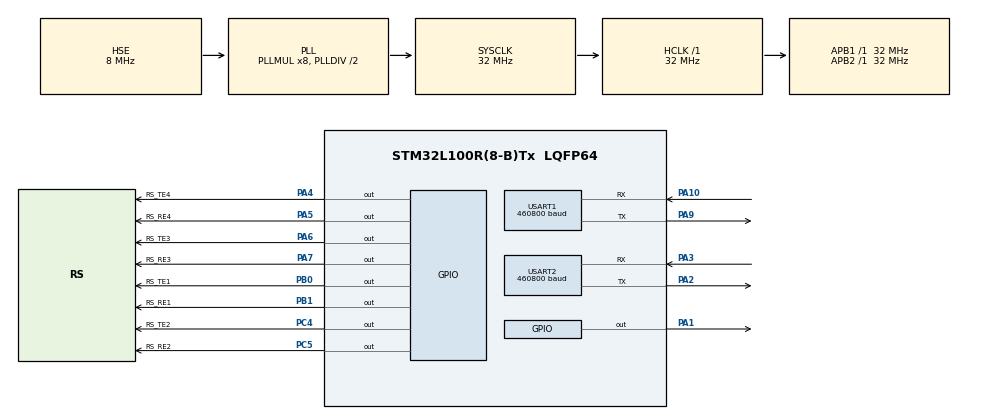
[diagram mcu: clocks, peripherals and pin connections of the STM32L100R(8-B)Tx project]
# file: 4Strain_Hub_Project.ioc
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Mcu.Family=STM32L1
Mcu.Name=STM32L100R(8-B)Tx
Mcu.Package=LQFP64
NVIC.PriorityGroup=NVIC_PRIORITYGROUP_4
NVIC.RCC_IRQn=true\:0\:0\:false\:false\:true\:true
NVIC.TIM10_IRQn=true\:2\:0\:true\:false\:true\:true
NVIC.USART1_IRQn=true\:5\:0\:true\:false\:true\:true
NVIC.USART2_IRQn=true\:1\:0\:true\:false\:true\:true
PA1.GPIO_Speed=GPIO_SPEED_FREQ_VERY_HIGH
PA1.Signal=GPIO_Output
PA10.Mode=Asynchronous
PA10.Signal=USART1_RX
PA13.Mode=Serial_Wire
PA13.Signal=SYS_JTMS-SWDIO
PA14.Mode=Serial_Wire
PA14.Signal=SYS_JTCK-SWCLK
PA2.Mode=Asynchronous
PA2.Signal=USART2_TX
PA3.Mode=Asynchronous
PA3.Signal=USART2_RX
PA4.GPIO_Label=RS_TE4
PA4.GPIO_PuPd=GPIO_NOPULL
PA4.GPIO_Speed=GPIO_SPEED_FREQ_VERY_HIGH
PA4.Signal=GPIO_Output
PA5.GPIO_Label=RS_RE4
PA5.GPIO_PuPd=GPIO_NOPULL
PA5.GPIO_Speed=GPIO_SPEED_FREQ_VERY_HIGH
PA5.Signal=GPIO_Output
PA6.GPIO_Label=RS_TE3
PA6.GPIO_PuPd=GPIO_NOPULL
PA6.GPIO_Speed=GPIO_SPEED_FREQ_VERY_HIGH
PA6.Signal=GPIO_Output
PA7.GPIO_Label=RS_RE3
PA7.GPIO_PuPd=GPIO_NOPULL
PA7.GPIO_Speed=GPIO_SPEED_FREQ_VERY_HIGH
PA7.Signal=GPIO_Output
PA9.Mode=Asynchronous
PA9.Signal=USART1_TX
PB0.GPIO_Label=RS_TE1
PB0.GPIO_PuPd=GPIO_NOPULL
PB0.GPIO_Speed=GPIO_SPEED_FREQ_VERY_HIGH
PB0.Signal=GPIO_Output
PB1.GPIO_Label=RS_RE1
PB1.GPIO_PuPd=GPIO_NOPULL
PB1.GPIO_Speed=GPIO_SPEED_FREQ_VERY_HIGH
PB1.Signal=GPIO_Output
PC4.GPIO_Label=RS_TE2
PC4.GPIO_PuPd=GPIO_NOPULL
PC4.GPIO_Speed=GPIO_SPEED_FREQ_VERY_HIGH
PC4.Signal=GPIO_Output
PC5.GPIO_Label=RS_RE2
PC5.GPIO_PuPd=GPIO_NOPULL
PC5.GPIO_Speed=GPIO_SPEED_FREQ_VERY_HIGH
PC5.Signal=GPIO_Output
PH0-OSC_IN.Mode=HSE-External-Oscillator
PH0-OSC_IN.Signal=RCC_OSC_IN
PH1-OSC_OUT.Mode=HSE-External-Oscillator
PH1-OSC_OUT.Signal=RCC_OSC_OUT
ProjectManager.HeapSize=0x200
ProjectManager.StackSize=0x400
ProjectManager.TargetToolchain=MDK-ARM V5
RCC.48MHZClocksFreq_Value=32000000
RCC.AHBFreq_Value=32000000
RCC.APB1Freq_Value=32000000
RCC.APB1TimFreq_Value=32000000
RCC.APB2Freq_Value=32000000
RCC.APB2TimFreq_Value=32000000
RCC.HCLKFreq_Value=32000000
RCC.HSE_VALUE=8000000
RCC.HSI_VALUE=16000000
RCC.LSE_VALUE=32768
RCC.MSI_VALUE=2097000
RCC.PLLMUL=RCC_PLL_MUL8
RCC.PLLSourceVirtual=RCC_PLLSOURCE_HSE
RCC.SYSCLKFreq_VALUE=32000000
RCC.SYSCLKSource=RCC_SYSCLKSOURCE_PLLCLK
RCC.VCOOutputFreq_Value=64000000
TIM10.Period=10000
TIM10.Prescaler=31
USART1.BaudRate=460800
USART1.VirtualMode=VM_ASYNC
USART2.BaudRate=460800
USART2.VirtualMode=VM_ASYNC
VP_TIM10_VS_ClockSourceINT.Mode=Internal
board=custom

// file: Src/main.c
/**
  ******************************************************************************
  * @file           : main.c
  * @brief          : Main program body
  ******************************************************************************
  ** This notice applies to any and all portions of this file
  * that are not between comment pairs USER CODE BEGIN and
  * USER CODE END. Other portions of this file, whether
  * inserted by the user or by software development tools
  * are owned by their respective copyright owners.
  *
  * COPYRIGHT(c) 2018 STMicroelectronics
  *
  * Redistribution and use in source and binary forms, with or without modification,
  * are permitted provided that the following conditions are met:
  *   1. Redistributions of source code must retain the above copyright notice,
  *      this list of conditions and the following disclaimer.
  *   2. Redistributions in binary form must reproduce the above copyright notice,
  *      this list of conditions and the following disclaimer in the documentation
  *      and/or other materials provided with the distribution.
  *   3. Neither the name of STMicroelectronics nor the names of its contributors
  *      may be used to endorse or promote products derived from this software
  *      without specific prior written permission.
  *
  * THIS SOFTWARE IS PROVIDED BY THE COPYRIGHT HOLDERS AND CONTRIBUTORS "AS IS"
  * AND ANY EXPRESS OR IMPLIED WARRANTIES, INCLUDING, BUT NOT LIMITED TO, THE
  * IMPLIED WARRANTIES OF MERCHANTABILITY AND FITNESS FOR A PARTICULAR PURPOSE ARE
  * DISCLAIMED. IN NO EVENT SHALL THE COPYRIGHT HOLDER OR CONTRIBUTORS BE LIABLE
  * FOR ANY DIRECT, INDIRECT, INCIDENTAL, SPECIAL, EXEMPLARY, OR CONSEQUENTIAL
  * DAMAGES (INCLUDING, BUT NOT LIMITED TO, PROCUREMENT OF SUBSTITUTE GOODS OR
  * SERVICES; LOSS OF USE, DATA, OR PROFITS; OR BUSINESS INTERRUPTION) HOWEVER
  * CAUSED AND ON ANY THEORY OF LIABILITY, WHETHER IN CONTRACT, STRICT LIABILITY,
  * OR TORT (INCLUDING NEGLIGENCE OR OTHERWISE) ARISING IN ANY WAY OUT OF THE USE
  * OF THIS SOFTWARE, EVEN IF ADVISED OF THE POSSIBILITY OF SUCH DAMAGE.
  *
  ******************************************************************************
  */
#include "main.h"
#include "stm32l1xx_hal.h"

TIM_HandleTypeDef htim10;

UART_HandleTypeDef huart1;
UART_HandleTypeDef huart2;

/* USER CODE BEGIN PV */
/* Private variables ---------------------------------------------------------*/
uint8_t x, data0;
/* USER CODE END PV */

void SystemClock_Config(void);
static void MX_GPIO_Init(void);
static void MX_TIM10_Init(void);
static void MX_USART2_UART_Init(void);
static void MX_USART1_UART_Init(void);

/* USER CODE BEGIN PFP */
/* Private function prototypes -----------------------------------------------*/

/* USER CODE END PFP */

int main(void)
{

  /* MCU Configuration----------------------------------------------------------*/

  /* Reset of all peripherals, Initializes the Flash interface and the Systick. */
  HAL_Init();

  /* Configure the system clock */
  SystemClock_Config();

  /* Initialize all configured peripherals */
  MX_GPIO_Init();
  MX_TIM10_Init();
  MX_USART2_UART_Init();
  MX_USART1_UART_Init();
  /* USER CODE BEGIN 2 */

	x = 1;

	USART2->CR1 |= USART_CR1_RXNEIE;

	HAL_TIM_Base_Start(&htim10);
	HAL_TIM_Base_Start_IT(&htim10);

  /* USER CODE END 2 */

  /* Infinite loop */
  /* USER CODE BEGIN WHILE */
  while (1)
  {
	HAL_UART_Receive_IT(&huart2, &data0, 1);
  /* USER CODE END WHILE */

  }

}

void SystemClock_Config(void)
{

  RCC_OscInitTypeDef RCC_OscInitStruct;
  RCC_ClkInitTypeDef RCC_ClkInitStruct;

    /**Configure the main internal regulator output voltage
    */
  __HAL_PWR_VOLTAGESCALING_CONFIG(PWR_REGULATOR_VOLTAGE_SCALE1);

    /**Initializes the CPU, AHB and APB busses clocks
    */
  RCC_OscInitStruct.OscillatorType = RCC_OSCILLATORTYPE_HSE;
  RCC_OscInitStruct.HSEState = RCC_HSE_ON;
  RCC_OscInitStruct.PLL.PLLState = RCC_PLL_ON;
  RCC_OscInitStruct.PLL.PLLSource = RCC_PLLSOURCE_HSE;
  RCC_OscInitStruct.PLL.PLLMUL = RCC_PLL_MUL8;
  RCC_OscInitStruct.PLL.PLLDIV = RCC_PLL_DIV2;
  if (HAL_RCC_OscConfig(&RCC_OscInitStruct) != HAL_OK)
  {
    _Error_Handler(__FILE__, __LINE__);
  }

    /**Initializes the CPU, AHB and APB busses clocks
    */
  RCC_ClkInitStruct.ClockType = RCC_CLOCKTYPE_HCLK|RCC_CLOCKTYPE_SYSCLK
                              |RCC_CLOCKTYPE_PCLK1|RCC_CLOCKTYPE_PCLK2;
  RCC_ClkInitStruct.SYSCLKSource = RCC_SYSCLKSOURCE_PLLCLK;
  RCC_ClkInitStruct.AHBCLKDivider = RCC_SYSCLK_DIV1;
  RCC_ClkInitStruct.APB1CLKDivider = RCC_HCLK_DIV1;
  RCC_ClkInitStruct.APB2CLKDivider = RCC_HCLK_DIV1;

  if (HAL_RCC_ClockConfig(&RCC_ClkInitStruct, FLASH_LATENCY_1) != HAL_OK)
  {
    _Error_Handler(__FILE__, __LINE__);
  }

    /**Configure the Systick interrupt time
    */
  HAL_SYSTICK_Config(HAL_RCC_GetHCLKFreq()/1000);

    /**Configure the Systick
    */
  HAL_SYSTICK_CLKSourceConfig(SYSTICK_CLKSOURCE_HCLK);

  /* SysTick_IRQn interrupt configuration */
  HAL_NVIC_SetPriority(SysTick_IRQn, 0, 0);
}

/* TIM10 init function */
static void MX_TIM10_Init(void)
{

  TIM_ClockConfigTypeDef sClockSourceConfig;

  htim10.Instance = TIM10;
  htim10.Init.Prescaler = 31;
  htim10.Init.CounterMode = TIM_COUNTERMODE_UP;
  htim10.Init.Period = 2000;//500 Hz
  htim10.Init.ClockDivision = TIM_CLOCKDIVISION_DIV1;
  if (HAL_TIM_Base_Init(&htim10) != HAL_OK)
  {
    _Error_Handler(__FILE__, __LINE__);
  }

  sClockSourceConfig.ClockSource = TIM_CLOCKSOURCE_INTERNAL;
  if (HAL_TIM_ConfigClockSource(&htim10, &sClockSourceConfig) != HAL_OK)
  {
    _Error_Handler(__FILE__, __LINE__);
  }

}

/* USART1 init function */
static void MX_USART1_UART_Init(void)
{

  huart1.Instance = USART1;
  huart1.Init.BaudRate = 460800;
  huart1.Init.WordLength = UART_WORDLENGTH_8B;
  huart1.Init.StopBits = UART_STOPBITS_1;
  huart1.Init.Parity = UART_PARITY_NONE;
  huart1.Init.Mode = UART_MODE_TX_RX;
  huart1.Init.HwFlowCtl = UART_HWCONTROL_NONE;
  huart1.Init.OverSampling = UART_OVERSAMPLING_16;
  if (HAL_UART_Init(&huart1) != HAL_OK)
  {
    _Error_Handler(__FILE__, __LINE__);
  }

}

/* USART2 init function */
static void MX_USART2_UART_Init(void)
{

  huart2.Instance = USART2;
  huart2.Init.BaudRate = 460800;
  huart2.Init.WordLength = UART_WORDLENGTH_8B;
  huart2.Init.StopBits = UART_STOPBITS_1;
  huart2.Init.Parity = UART_PARITY_NONE;
  huart2.Init.Mode = UART_MODE_TX_RX;
  huart2.Init.HwFlowCtl = UART_HWCONTROL_NONE;
  huart2.Init.OverSampling = UART_OVERSAMPLING_16;
  if (HAL_UART_Init(&huart2) != HAL_OK)
  {
    _Error_Handler(__FILE__, __LINE__);
  }

}

/** Configure pins as
        * Analog
        * Input
        * Output
        * EVENT_OUT
        * EXTI
*/
static void MX_GPIO_Init(void)
{

  GPIO_InitTypeDef GPIO_InitStruct;

  /* GPIO Ports Clock Enable */
  __HAL_RCC_GPIOH_CLK_ENABLE();
  __HAL_RCC_GPIOA_CLK_ENABLE();
  __HAL_RCC_GPIOC_CLK_ENABLE();
  __HAL_RCC_GPIOB_CLK_ENABLE();

  /*Configure GPIO pin Output Level */
  HAL_GPIO_WritePin(GPIOA, GPIO_PIN_1|RS_TE4_Pin|RS_RE4_Pin|RS_TE3_Pin
                          |RS_RE3_Pin, GPIO_PIN_RESET);

  /*Configure GPIO pin Output Level */
  HAL_GPIO_WritePin(GPIOC, RS_TE2_Pin|RS_RE2_Pin, GPIO_PIN_RESET);

  /*Configure GPIO pin Output Level */
  HAL_GPIO_WritePin(GPIOB, RS_TE1_Pin|RS_RE1_Pin, GPIO_PIN_RESET);

  /*Configure GPIO pins : PA1 RS_TE4_Pin RS_RE4_Pin RS_TE3_Pin
                           RS_RE3_Pin */
  GPIO_InitStruct.Pin = GPIO_PIN_1|RS_TE4_Pin|RS_RE4_Pin|RS_TE3_Pin
                          |RS_RE3_Pin;
  GPIO_InitStruct.Mode = GPIO_MODE_OUTPUT_PP;
  GPIO_InitStruct.Pull = GPIO_NOPULL;
  GPIO_InitStruct.Speed = GPIO_SPEED_FREQ_VERY_HIGH;
  HAL_GPIO_Init(GPIOA, &GPIO_InitStruct);

  /*Configure GPIO pins : RS_TE2_Pin RS_RE2_Pin */
  GPIO_InitStruct.Pin = RS_TE2_Pin|RS_RE2_Pin;
  GPIO_InitStruct.Mode = GPIO_MODE_OUTPUT_PP;
  GPIO_InitStruct.Pull = GPIO_NOPULL;
  GPIO_InitStruct.Speed = GPIO_SPEED_FREQ_VERY_HIGH;
  HAL_GPIO_Init(GPIOC, &GPIO_InitStruct);

  /*Configure GPIO pins : RS_TE1_Pin RS_RE1_Pin */
  GPIO_InitStruct.Pin = RS_TE1_Pin|RS_RE1_Pin;
  GPIO_InitStruct.Mode = GPIO_MODE_OUTPUT_PP;
  GPIO_InitStruct.Pull = GPIO_NOPULL;
  GPIO_InitStruct.Speed = GPIO_SPEED_FREQ_VERY_HIGH;
  HAL_GPIO_Init(GPIOB, &GPIO_InitStruct);

}

void _Error_Handler(char *file, int line)
{
  while(1)
  {
  }
}

/************************ (C) COPYRIGHT STMicroelectronics *****END OF FILE****/
